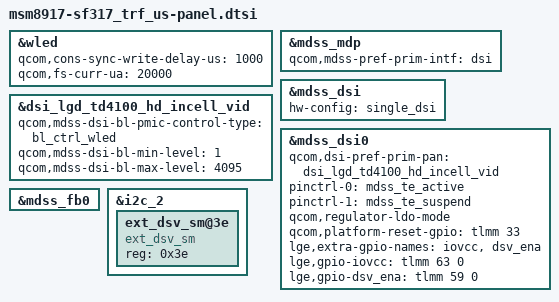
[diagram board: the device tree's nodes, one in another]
/*
 * Copyright (c) 2016, The Linux Foundation. All rights reserved.
 *
 * This program is free software; you can redistribute it and/or modify
 * it under the terms of the GNU General Public License version 2 and
 * only version 2 as published by the Free Software Foundation.
 *
 * This program is distributed in the hope that it will be useful,
 * but WITHOUT ANY WARRANTY; without even the implied warranty of
 * MERCHANTABILITY or FITNESS FOR A PARTICULAR PURPOSE.  See the
 * GNU General Public License for more details.
 */

#include "../dsi-panel-lgd-td4100-hd-video.dtsi"

&wled {
	qcom,cons-sync-write-delay-us = <1000>;
	qcom,fs-curr-ua = <20000>;
};

&mdss_mdp {
	qcom,mdss-pref-prim-intf = "dsi";
};

&mdss_dsi {
	hw-config = "single_dsi";
};

&dsi_lgd_td4100_hd_incell_vid {
	qcom,mdss-dsi-bl-pmic-control-type = "bl_ctrl_wled";
	qcom,mdss-dsi-bl-min-level = <1>;
	qcom,mdss-dsi-bl-max-level = <4095>;
};

&mdss_dsi0 {
	qcom,dsi-pref-prim-pan = <&dsi_lgd_td4100_hd_incell_vid>;
	pinctrl-names = "mdss_default", "mdss_sleep";
	pinctrl-0 = <&mdss_te_active>;
	pinctrl-1 = <&mdss_te_suspend>;
	qcom,regulator-ldo-mode;
	qcom,platform-reset-gpio = <&tlmm 33 0>;

	lge,extra-gpio-names = "iovcc", "dsv_ena";
	lge,gpio-iovcc = <&tlmm 63 0>;
	lge,gpio-dsv_ena = <&tlmm 59 0>;
};

&mdss_fb0 {
	/delete-property/ qcom,mdss-fb-splash-logo-enabled;
};

&i2c_2 {
	ext_dsv_sm@3e{
		status = "ok";
		compatible = "ext_dsv_sm";
		reg = <0x3e>;
	};
};
